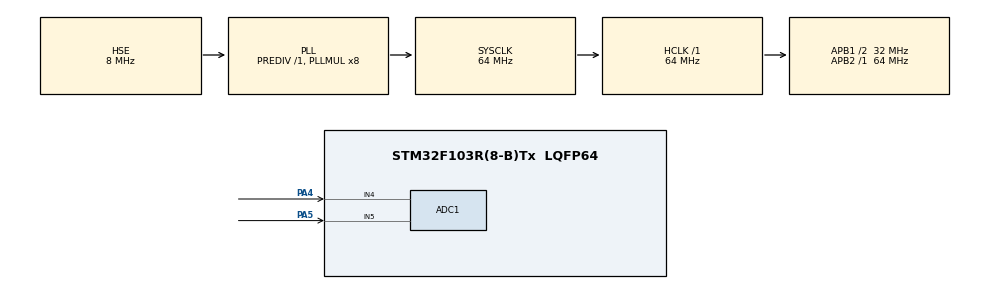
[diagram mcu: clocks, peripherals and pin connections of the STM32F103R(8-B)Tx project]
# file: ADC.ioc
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ADC1.Channel-23\#ChannelInjectedConversion=ADC_CHANNEL_4
ADC1.Channel-24\#ChannelInjectedConversion=ADC_CHANNEL_5
ADC1.ContinuousConvMode=ENABLE
ADC1.DataAlign=ADC_DATAALIGN_RIGHT
ADC1.DiscontinuousConvMode=DISABLE
ADC1.EnableAnalogWatchDog=false
ADC1.EnableRegularConversion=DISABLE
ADC1.InjNumberOfConversion=2
ADC1.InjectedOffset-23\#ChannelInjectedConversion=0
ADC1.InjectedOffset-24\#ChannelInjectedConversion=0
ADC1.Rank-23\#ChannelInjectedConversion=1
ADC1.Rank-24\#ChannelInjectedConversion=2
ADC1.SamplingTime-23\#ChannelInjectedConversion=ADC_SAMPLETIME_1CYCLE_5
ADC1.SamplingTime-24\#ChannelInjectedConversion=ADC_SAMPLETIME_1CYCLE_5
ADC1.ScanConvMode=ADC_SCAN_ENABLE
ADC1.master=1
Mcu.Family=STM32F1
Mcu.Name=STM32F103R(8-B)Tx
Mcu.Package=LQFP64
NVIC.ADC1_2_IRQn=true\:0\:0\:false\:false\:true\:true
NVIC.PriorityGroup=NVIC_PRIORITYGROUP_4
NVIC.TIM1_UP_IRQn=true\:0\:0\:false\:false\:true\:true
PA13.Mode=Serial_Wire
PA13.Signal=SYS_JTMS-SWDIO
PA14.Mode=Serial_Wire
PA14.Signal=SYS_JTCK-SWCLK
PA4.Signal=ADCx_IN4
PA5.Signal=ADCx_IN5
PD0-OSC_IN.Mode=HSE-External-Oscillator
PD0-OSC_IN.Signal=RCC_OSC_IN
PD1-OSC_OUT.Mode=HSE-External-Oscillator
PD1-OSC_OUT.Signal=RCC_OSC_OUT
ProjectManager.HeapSize=0x200
ProjectManager.StackSize=0x400
ProjectManager.TargetToolchain=MDK-ARM V5
RCC.ADCPresc=RCC_ADCPCLK2_DIV8
RCC.AHBFreq_Value=64000000
RCC.APB1CLKDivider=RCC_HCLK_DIV2
RCC.APB1Freq_Value=32000000
RCC.APB1TimFreq_Value=64000000
RCC.APB2Freq_Value=64000000
RCC.APB2TimFreq_Value=64000000
RCC.HCLKFreq_Value=64000000
RCC.PLLMUL=RCC_PLL_MUL8
RCC.PLLSourceVirtual=RCC_PLLSOURCE_HSE
RCC.SYSCLKFreq_VALUE=64000000
RCC.SYSCLKSource=RCC_SYSCLKSOURCE_PLLCLK
RCC.USBFreq_Value=64000000
SH.ADCx_IN4.0=ADC1_IN4,IN4
SH.ADCx_IN5.0=ADC1_IN5,IN5
TIM1.Channel-Output\ Compare1\ No\ Output=TIM_CHANNEL_1
TIM1.Period=4
TIM1.Prescaler=31999
VP_TIM1_VS_ClockSourceINT.Mode=Internal
VP_TIM1_VS_no_output1.Mode=Output Compare1 No Output
board=ADC

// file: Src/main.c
/**
  ******************************************************************************
  * @file           : main.c
  * @brief          : Main program body
  ******************************************************************************
  ** This notice applies to any and all portions of this file
  * that are not between comment pairs USER CODE BEGIN and
  * USER CODE END. Other portions of this file, whether
  * inserted by the user or by software development tools
  * are owned by their respective copyright owners.
  *
  * COPYRIGHT(c) 2018 STMicroelectronics
  *
  * Redistribution and use in source and binary forms, with or without modification,
  * are permitted provided that the following conditions are met:
  *   1. Redistributions of source code must retain the above copyright notice,
  *      this list of conditions and the following disclaimer.
  *   2. Redistributions in binary form must reproduce the above copyright notice,
  *      this list of conditions and the following disclaimer in the documentation
  *      and/or other materials provided with the distribution.
  *   3. Neither the name of STMicroelectronics nor the names of its contributors
  *      may be used to endorse or promote products derived from this software
  *      without specific prior written permission.
  *
  * THIS SOFTWARE IS PROVIDED BY THE COPYRIGHT HOLDERS AND CONTRIBUTORS "AS IS"
  * AND ANY EXPRESS OR IMPLIED WARRANTIES, INCLUDING, BUT NOT LIMITED TO, THE
  * IMPLIED WARRANTIES OF MERCHANTABILITY AND FITNESS FOR A PARTICULAR PURPOSE ARE
  * DISCLAIMED. IN NO EVENT SHALL THE COPYRIGHT HOLDER OR CONTRIBUTORS BE LIABLE
  * FOR ANY DIRECT, INDIRECT, INCIDENTAL, SPECIAL, EXEMPLARY, OR CONSEQUENTIAL
  * DAMAGES (INCLUDING, BUT NOT LIMITED TO, PROCUREMENT OF SUBSTITUTE GOODS OR
  * SERVICES; LOSS OF USE, DATA, OR PROFITS; OR BUSINESS INTERRUPTION) HOWEVER
  * CAUSED AND ON ANY THEORY OF LIABILITY, WHETHER IN CONTRACT, STRICT LIABILITY,
  * OR TORT (INCLUDING NEGLIGENCE OR OTHERWISE) ARISING IN ANY WAY OUT OF THE USE
  * OF THIS SOFTWARE, EVEN IF ADVISED OF THE POSSIBILITY OF SUCH DAMAGE.
  *
  ******************************************************************************
  */
#include "main.h"
#include "stm32f1xx_hal.h"

ADC_HandleTypeDef hadc1;

TIM_HandleTypeDef htim1;

/* USER CODE BEGIN PV */
/* Private variables ---------------------------------------------------------*/
volatile uint16_t ADC_Data[2];

/* USER CODE END PV */

void SystemClock_Config(void);
static void MX_GPIO_Init(void);
static void MX_ADC1_Init(void);
static void MX_TIM1_Init(void);

/* USER CODE BEGIN PFP */
/* Private function prototypes -----------------------------------------------*/

/* USER CODE END PFP */

int main(void)
{

  /* MCU Configuration----------------------------------------------------------*/

  /* Reset of all peripherals, Initializes the Flash interface and the Systick. */
  HAL_Init();

  /* Configure the system clock */
  SystemClock_Config();

  /* Initialize all configured peripherals */
  MX_GPIO_Init();
  MX_ADC1_Init();
  MX_TIM1_Init();
  /* USER CODE BEGIN 2 */
  HAL_ADCEx_Calibration_Start(&hadc1);
HAL_ADCEx_InjectedStart_IT(&hadc1);
  /* USER CODE END 2 */

  /* Infinite loop */
  while (1)
  {
    uint32_t i = 0;
    i++;
    if (i>6500000)
    {
       HAL_ADCEx_InjectedStart_IT(&hadc1);
      i=0;
    }

  }

}

void SystemClock_Config(void)
{

  RCC_OscInitTypeDef RCC_OscInitStruct;
  RCC_ClkInitTypeDef RCC_ClkInitStruct;
  RCC_PeriphCLKInitTypeDef PeriphClkInit;

    /**Initializes the CPU, AHB and APB busses clocks
    */
  RCC_OscInitStruct.OscillatorType = RCC_OSCILLATORTYPE_HSE;
  RCC_OscInitStruct.HSEState = RCC_HSE_ON;
  RCC_OscInitStruct.HSEPredivValue = RCC_HSE_PREDIV_DIV1;
  RCC_OscInitStruct.HSIState = RCC_HSI_ON;
  RCC_OscInitStruct.PLL.PLLState = RCC_PLL_ON;
  RCC_OscInitStruct.PLL.PLLSource = RCC_PLLSOURCE_HSE;
  RCC_OscInitStruct.PLL.PLLMUL = RCC_PLL_MUL8;
  if (HAL_RCC_OscConfig(&RCC_OscInitStruct) != HAL_OK)
  {
    _Error_Handler(__FILE__, __LINE__);
  }

    /**Initializes the CPU, AHB and APB busses clocks
    */
  RCC_ClkInitStruct.ClockType = RCC_CLOCKTYPE_HCLK|RCC_CLOCKTYPE_SYSCLK
                              |RCC_CLOCKTYPE_PCLK1|RCC_CLOCKTYPE_PCLK2;
  RCC_ClkInitStruct.SYSCLKSource = RCC_SYSCLKSOURCE_PLLCLK;
  RCC_ClkInitStruct.AHBCLKDivider = RCC_SYSCLK_DIV1;
  RCC_ClkInitStruct.APB1CLKDivider = RCC_HCLK_DIV2;
  RCC_ClkInitStruct.APB2CLKDivider = RCC_HCLK_DIV1;

  if (HAL_RCC_ClockConfig(&RCC_ClkInitStruct, FLASH_LATENCY_2) != HAL_OK)
  {
    _Error_Handler(__FILE__, __LINE__);
  }

  PeriphClkInit.PeriphClockSelection = RCC_PERIPHCLK_ADC;
  PeriphClkInit.AdcClockSelection = RCC_ADCPCLK2_DIV8;
  if (HAL_RCCEx_PeriphCLKConfig(&PeriphClkInit) != HAL_OK)
  {
    _Error_Handler(__FILE__, __LINE__);
  }

    /**Configure the Systick interrupt time
    */
  HAL_SYSTICK_Config(HAL_RCC_GetHCLKFreq()/1000);

    /**Configure the Systick
    */
  HAL_SYSTICK_CLKSourceConfig(SYSTICK_CLKSOURCE_HCLK);

  /* SysTick_IRQn interrupt configuration */
  HAL_NVIC_SetPriority(SysTick_IRQn, 0, 0);
}

/* ADC1 init function */
static void MX_ADC1_Init(void)
{

  ADC_InjectionConfTypeDef sConfigInjected;

    /**Common config
    */
  hadc1.Instance = ADC1;
  hadc1.Init.ScanConvMode = ADC_SCAN_ENABLE;
  hadc1.Init.ContinuousConvMode = ENABLE;
  hadc1.Init.DiscontinuousConvMode = DISABLE;
  hadc1.Init.ExternalTrigConv = ADC_SOFTWARE_START;
  hadc1.Init.DataAlign = ADC_DATAALIGN_RIGHT;
  hadc1.Init.NbrOfConversion = 1;
  if (HAL_ADC_Init(&hadc1) != HAL_OK)
  {
    _Error_Handler(__FILE__, __LINE__);
  }

    /**Configure Injected Channel
    */
  sConfigInjected.InjectedChannel = ADC_CHANNEL_4;
  sConfigInjected.InjectedRank = ADC_INJECTED_RANK_1;
  sConfigInjected.InjectedNbrOfConversion = 2;
  sConfigInjected.InjectedSamplingTime = ADC_SAMPLETIME_1CYCLE_5;
  sConfigInjected.ExternalTrigInjecConv = ADC_INJECTED_SOFTWARE_START;
  sConfigInjected.AutoInjectedConv = DISABLE;
  sConfigInjected.InjectedDiscontinuousConvMode = DISABLE;
  sConfigInjected.InjectedOffset = 0;
  if (HAL_ADCEx_InjectedConfigChannel(&hadc1, &sConfigInjected) != HAL_OK)
  {
    _Error_Handler(__FILE__, __LINE__);
  }

    /**Configure Injected Channel
    */
  sConfigInjected.InjectedChannel = ADC_CHANNEL_5;
  sConfigInjected.InjectedRank = ADC_INJECTED_RANK_2;
  if (HAL_ADCEx_InjectedConfigChannel(&hadc1, &sConfigInjected) != HAL_OK)
  {
    _Error_Handler(__FILE__, __LINE__);
  }

}

/* TIM1 init function */
static void MX_TIM1_Init(void)
{

  TIM_ClockConfigTypeDef sClockSourceConfig;
  TIM_MasterConfigTypeDef sMasterConfig;
  TIM_OC_InitTypeDef sConfigOC;
  TIM_BreakDeadTimeConfigTypeDef sBreakDeadTimeConfig;

  htim1.Instance = TIM1;
  htim1.Init.Prescaler = 31999;
  htim1.Init.CounterMode = TIM_COUNTERMODE_UP;
  htim1.Init.Period = 4;
  htim1.Init.ClockDivision = TIM_CLOCKDIVISION_DIV1;
  htim1.Init.RepetitionCounter = 0;
  htim1.Init.AutoReloadPreload = TIM_AUTORELOAD_PRELOAD_DISABLE;
  if (HAL_TIM_Base_Init(&htim1) != HAL_OK)
  {
    _Error_Handler(__FILE__, __LINE__);
  }

  sClockSourceConfig.ClockSource = TIM_CLOCKSOURCE_INTERNAL;
  if (HAL_TIM_ConfigClockSource(&htim1, &sClockSourceConfig) != HAL_OK)
  {
    _Error_Handler(__FILE__, __LINE__);
  }

  if (HAL_TIM_OC_Init(&htim1) != HAL_OK)
  {
    _Error_Handler(__FILE__, __LINE__);
  }

  sMasterConfig.MasterOutputTrigger = TIM_TRGO_RESET;
  sMasterConfig.MasterSlaveMode = TIM_MASTERSLAVEMODE_DISABLE;
  if (HAL_TIMEx_MasterConfigSynchronization(&htim1, &sMasterConfig) != HAL_OK)
  {
    _Error_Handler(__FILE__, __LINE__);
  }

  sConfigOC.OCMode = TIM_OCMODE_TIMING;
  sConfigOC.Pulse = 0;
  sConfigOC.OCPolarity = TIM_OCPOLARITY_HIGH;
  sConfigOC.OCNPolarity = TIM_OCNPOLARITY_HIGH;
  sConfigOC.OCFastMode = TIM_OCFAST_DISABLE;
  sConfigOC.OCIdleState = TIM_OCIDLESTATE_RESET;
  sConfigOC.OCNIdleState = TIM_OCNIDLESTATE_RESET;
  if (HAL_TIM_OC_ConfigChannel(&htim1, &sConfigOC, TIM_CHANNEL_1) != HAL_OK)
  {
    _Error_Handler(__FILE__, __LINE__);
  }

  sBreakDeadTimeConfig.OffStateRunMode = TIM_OSSR_DISABLE;
  sBreakDeadTimeConfig.OffStateIDLEMode = TIM_OSSI_DISABLE;
  sBreakDeadTimeConfig.LockLevel = TIM_LOCKLEVEL_OFF;
  sBreakDeadTimeConfig.DeadTime = 0;
  sBreakDeadTimeConfig.BreakState = TIM_BREAK_DISABLE;
  sBreakDeadTimeConfig.BreakPolarity = TIM_BREAKPOLARITY_HIGH;
  sBreakDeadTimeConfig.AutomaticOutput = TIM_AUTOMATICOUTPUT_DISABLE;
  if (HAL_TIMEx_ConfigBreakDeadTime(&htim1, &sBreakDeadTimeConfig) != HAL_OK)
  {
    _Error_Handler(__FILE__, __LINE__);
  }

}

/** Configure pins as
        * Analog
        * Input
        * Output
        * EVENT_OUT
        * EXTI
*/
static void MX_GPIO_Init(void)
{

  /* GPIO Ports Clock Enable */
  __HAL_RCC_GPIOD_CLK_ENABLE();
  __HAL_RCC_GPIOA_CLK_ENABLE();

}

/* USER CODE BEGIN 4 */
void HAL_ADCEx_InjectedConvCpltCallback(ADC_HandleTypeDef* hadc1)
{
    ADC_Data[0]=HAL_ADCEx_InjectedGetValue(hadc1,ADC_INJECTED_RANK_1);
    ADC_Data[1]=HAL_ADCEx_InjectedGetValue(hadc1,ADC_INJECTED_RANK_2);
   HAL_ADCEx_InjectedStart_IT(hadc1);
}
void HAL_ADCEx_InjectedConvCpltCallback2(ADC_HandleTypeDef* hadc1)
{
   // ADC_Data[0]=HAL_ADCEx_InjectedGetValue(hadc1,ADC_INJECTED_RANK_1);
   // ADC_Data[1]=HAL_ADCEx_InjectedGetValue(hadc1,ADC_INJECTED_RANK_2);
   // HAL_ADCEx_InjectedStart_IT(hadc1);
}

void HAL_ADC_ConvCpltCallback(ADC_HandleTypeDef* hadc1)
{
//	HAL_ADC_Start_IT(hadc1);
}
/* USER CODE END 4 */

void _Error_Handler(char *file, int line)
{
  while(1)
  {
  }
}

/************************ (C) COPYRIGHT STMicroelectronics *****END OF FILE****/
